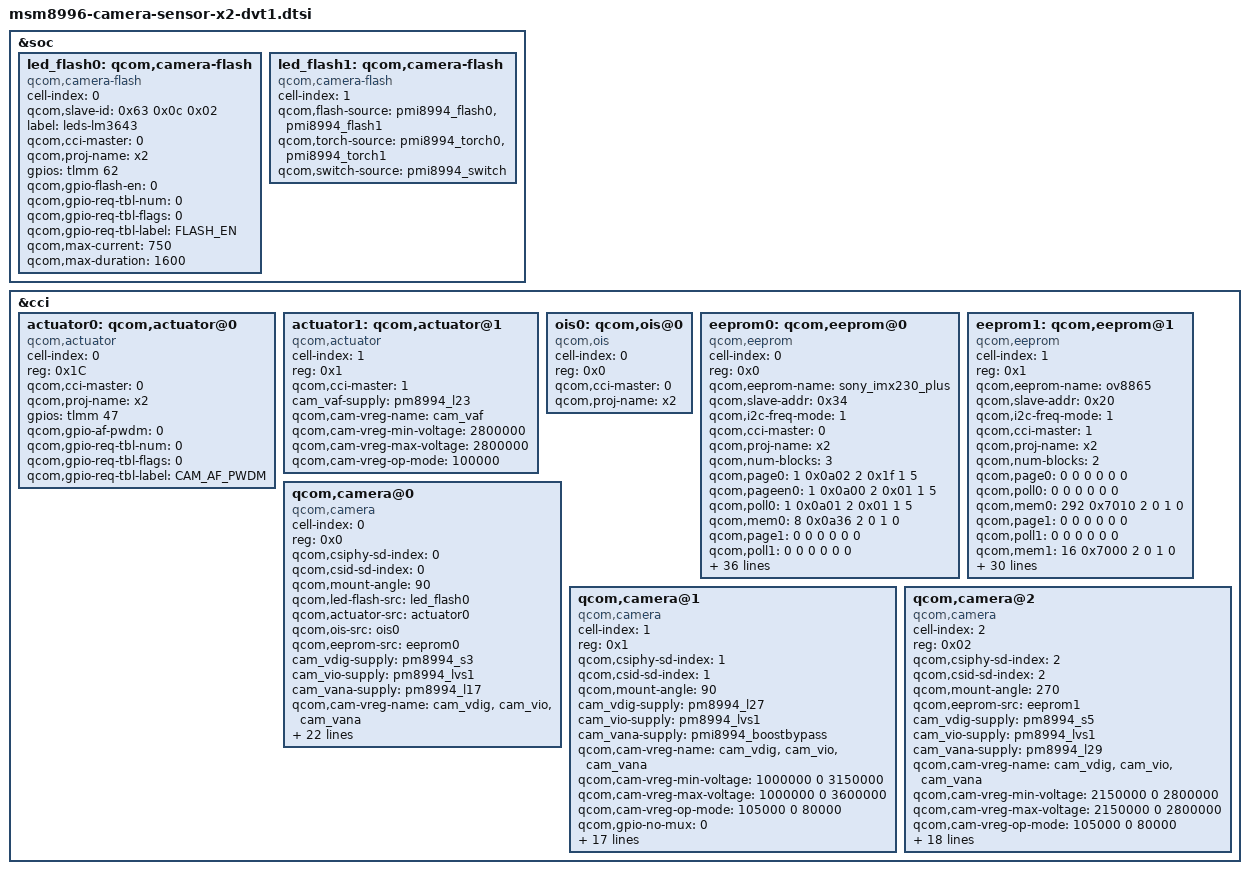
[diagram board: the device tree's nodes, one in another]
/*
 * Copyright (c) 2015 The Linux Foundation. All rights reserved.
 *
 * This program is free software; you can redistribute it and/or modify
 * it under the terms of the GNU General Public License version 2 and
 * only version 2 as published by the Free Software Foundation.
 *
 * This program is distributed in the hope that it will be useful,
 * but WITHOUT ANY WARRANTY; without even the implied warranty of
 * MERCHANTABILITY or FITNESS FOR A PARTICULAR PURPOSE.  See the
 * GNU General Public License for more details.
 */

&soc {
	led_flash0: qcom,camera-flash {
		cell-index = <0>;
		qcom,slave-id = <0x63 0x0c 0x02>;
		compatible = "qcom,camera-flash";
		label = "leds-lm3643";
		qcom,cci-master = <0>;
		qcom,proj-name = "x2";
		gpios = <&tlmm 62 0>;
		qcom,gpio-flash-en = <0>;
		qcom,gpio-req-tbl-num = <0>;
		qcom,gpio-req-tbl-flags = <0>;
		qcom,gpio-req-tbl-label = "FLASH_EN";
		qcom,max-current = <750>;
		qcom,max-duration = <1600>;
	};

	led_flash1: qcom,camera-flash {
		cell-index = <1>;
		compatible = "qcom,camera-flash";
		qcom,flash-source = <&pmi8994_flash0 &pmi8994_flash1>;
		qcom,torch-source = <&pmi8994_torch0 &pmi8994_torch1>;
		qcom,switch-source = <&pmi8994_switch>;
	};
};

&cci {
	actuator0: qcom,actuator@0 {
		cell-index = <0>;
		reg = <0x1C>;
		compatible = "qcom,actuator";
		qcom,cci-master = <0>;
		qcom,proj-name = "x2";
		gpios = <&tlmm 47 0>;
		qcom,gpio-af-pwdm = <0>;
		qcom,gpio-req-tbl-num = <0>;
		qcom,gpio-req-tbl-flags = <0>;
		qcom,gpio-req-tbl-label =  "CAM_AF_PWDM";
	};

	actuator1: qcom,actuator@1 {
		cell-index = <1>;
		reg = <0x1>;
		compatible = "qcom,actuator";
		qcom,cci-master = <1>;
		cam_vaf-supply = <&pm8994_l23>;
		qcom,cam-vreg-name = "cam_vaf";
		qcom,cam-vreg-min-voltage = <2800000>;
		qcom,cam-vreg-max-voltage = <2800000>;
		qcom,cam-vreg-op-mode = <100000>;
	};

	ois0: qcom,ois@0 {
		cell-index = <0>;
		reg = <0x0>;
		compatible = "qcom,ois";
		qcom,cci-master = <0>;
		qcom,proj-name = "x2";
		/*
		cam_vaf-supply = <&pm8994_l23>;
		qcom,cam-vreg-name = "cam_vaf";
		qcom,cam-vreg-min-voltage = <2800000>;
		qcom,cam-vreg-max-voltage = <2800000>;
		qcom,cam-vreg-op-mode = <100000>;
		*/
	};

	eeprom0: qcom,eeprom@0 {
		cell-index = <0>;
		reg = <0x0>;
		qcom,eeprom-name = "sony_imx230_plus";
		compatible = "qcom,eeprom";
		qcom,slave-addr = <0x34>;
		qcom,i2c-freq-mode = <1>;
		qcom,cci-master = <0>;
		qcom,proj-name = "x2";
		qcom,num-blocks = <3>;

		qcom,page0 = <1 0x0a02 2 0x1f 1 5>;
		qcom,pageen0 = <1 0x0a00 2 0x01 1 5>;
		qcom,poll0 = <1 0x0a01 2 0x01 1 5>;
		qcom,mem0 = <8 0x0a36 2 0 1 0>;

		qcom,page1 = <0 0 0 0 0 0>;
		qcom,poll1 = <0 0 0 0 0 0>;
		qcom,saddr1 = <0xa1>;
		qcom,mem1 = <547 0x0000 2 0 1 0>;

		qcom,page2 = <0 0 0 0 0 0>;
		qcom,poll2 = <0 0 0 0 0 0>;
		qcom,saddr2 = <0xa1>;
		qcom,mem2 = <13 0x0300 2 0 1 0>;

		cam_vdig-supply = <&pm8994_s3>;
		cam_vio-supply = <&pm8994_lvs1>;
		cam_vana-supply = <&pm8994_l17>;
		qcom,cam-vreg-name = "cam_vdig", "cam_vio", "cam_vana";
		qcom,cam-vreg-min-voltage = <1300000 0 2500000>;
		qcom,cam-vreg-max-voltage = <1300000 0 2500000>;
		qcom,cam-vreg-op-mode = <105000 0 80000>;
		qcom,gpio-no-mux = <0>;
		pinctrl-names = "cam_default", "cam_suspend";
		pinctrl-0 = <&cam_sensor_mclk0_active &cam_sensor_rear_active>;
		pinctrl-1 = <&cam_sensor_mclk0_suspend &cam_sensor_rear_suspend>;
		gpios = <&tlmm 13 0>,
			<&tlmm 47 0>,
			<&tlmm 29 0>;
		qcom,gpio-reset = <1>;
		qcom,gpio-standby = <2>;
		qcom,gpio-req-tbl-num = <0 1 2>;
		qcom,gpio-req-tbl-flags = <1 0 0>;
		qcom,gpio-req-tbl-label = "CAMIF_MCLK0",
					  "CAM_AF0",
					  "CAM_STANDBY0";
		qcom,cam-power-seq-type = "sensor_vreg", "sensor_vreg", "sensor_vreg",
			"sensor_gpio", "sensor_gpio" , "sensor_clk";
		qcom,cam-power-seq-val = "cam_vdig", "cam_vana", "cam_vio",
			"sensor_gpio_reset", "sensor_gpio_standby","sensor_cam_mclk";
		qcom,cam-power-seq-cfg-val = <1 1 1 1 1 24000000>;
		qcom,cam-power-seq-delay = <1 1 1 30 30 5>;
		status = "ok";
		clocks = <&clock_mmss clk_mclk0_clk_src>,
				<&clock_mmss clk_camss_mclk0_clk>;
		clock-names = "cam_src_clk", "cam_clk";
	};

	eeprom1: qcom,eeprom@1 {
		cell-index = <1>;
		reg = <0x1>;
		qcom,eeprom-name = "ov8865";
		compatible = "qcom,eeprom";
		qcom,slave-addr = <0x20>;
		qcom,i2c-freq-mode = <1>;
		qcom,cci-master = <1>;
		qcom,proj-name = "x2";
		qcom,num-blocks = <2>;

		qcom,page0 = <0 0 0 0 0 0>;
		qcom,poll0 = <0 0 0 0 0 0>;
		qcom,mem0 = <292 0x7010 2 0 1 0>;

		qcom,page1 = <0 0 0 0 0 0>;
		qcom,poll1 = <0 0 0 0 0 0>;
		qcom,mem1 = <16 0x7000 2 0 1 0>;

		cam_vdig-supply = <&pm8994_s5>;
		cam_vio-supply = <&pm8994_lvs1>;
		cam_vana-supply = <&pm8994_l29>;
		qcom,cam-vreg-name = "cam_vdig", "cam_vio", "cam_vana";
		qcom,cam-vreg-min-voltage = <2150000 0 2800000>;
		qcom,cam-vreg-max-voltage = <2150000 0 2800000>;
		qcom,cam-vreg-op-mode = <105000 0 80000>;
		qcom,gpio-no-mux = <0>;
		pinctrl-names = "cam_default", "cam_suspend";
		pinctrl-0 = <&cam_sensor_mclk2_active &cam_sensor_front_active>;
		pinctrl-1 = <&cam_sensor_mclk2_suspend &cam_sensor_front_suspend>;
		gpios = <&tlmm 15 0>,
			<&tlmm 23 0>,
			<&tlmm 26 0>;
		qcom,gpio-reset = <1>;
		qcom,gpio-standby = <2>;
		qcom,gpio-req-tbl-num = <0 1 2>;
		qcom,gpio-req-tbl-flags = <1 0 0>;
		qcom,gpio-req-tbl-label = "CAMIF_MCLK2",
					  "CAM_RESET2",
					  "CAM_STANDBY2";
		qcom,cam-power-seq-type = "sensor_vreg", "sensor_vreg", "sensor_vreg",
			"sensor_gpio", "sensor_gpio" , "sensor_clk";
		qcom,cam-power-seq-val = "cam_vdig", "cam_vana", "cam_vio",
			"sensor_gpio_reset", "sensor_gpio_standby","sensor_cam_mclk";
		qcom,cam-power-seq-cfg-val = <1 1 1 1 1 24000000>;
		qcom,cam-power-seq-delay = <1 1 1 30 30 5>;
		status = "ok";
		clocks = <&clock_mmss clk_mclk2_clk_src>,
				<&clock_mmss clk_camss_mclk2_clk>;
		clock-names = "cam_src_clk", "cam_clk";
	};

	qcom,camera@0 {
		cell-index = <0>;
		compatible = "qcom,camera";
		reg = <0x0>;
		qcom,csiphy-sd-index = <0>;
		qcom,csid-sd-index = <0>;
		qcom,mount-angle = <90>;
		qcom,led-flash-src = <&led_flash0>;
		qcom,actuator-src = <&actuator0>;
		qcom,ois-src = <&ois0>;
		qcom,eeprom-src = <&eeprom0>;
		cam_vdig-supply = <&pm8994_s3>;
		cam_vio-supply = <&pm8994_lvs1>;
		cam_vana-supply = <&pm8994_l17>;
		qcom,cam-vreg-name = "cam_vdig", "cam_vio", "cam_vana";
		qcom,cam-vreg-min-voltage = <1300000 0 2500000>;
		qcom,cam-vreg-max-voltage = <1300000 0 2500000>;
		qcom,cam-vreg-op-mode = <105000 0 80000>;
		qcom,gpio-no-mux = <0>;
		pinctrl-names = "cam_default", "cam_suspend";
		pinctrl-0 = <&cam_sensor_mclk0_active &cam_sensor_rear_active>;
		pinctrl-1 = <&cam_sensor_mclk0_suspend &cam_sensor_rear_suspend>;
		gpios = <&tlmm 13 0>,
			<&tlmm 62 0>,
			<&tlmm 47 0>,
			<&tlmm 29 0>;
		qcom,gpio-flash-en = <1>;
		qcom,gpio-vaf = <2>;
		qcom,gpio-standby = <3>;
		qcom,gpio-req-tbl-num = <0 1 2 3>;
		qcom,gpio-req-tbl-flags = <1 0 0 0>;
		qcom,gpio-req-tbl-label = "CAMIF_MCLK0",
					  "CAM_FLASH0",
					  "CAM_AF0",
					  "CAM_STANDBY0";
		qcom,sensor-position = <0>;
		qcom,sensor-mode = <0>;
		qcom,cci-master = <0>;
		qcom,proj-name = "x2";
		status = "ok";
		clocks = <&clock_mmss clk_mclk0_clk_src>,
				<&clock_mmss clk_camss_mclk0_clk>;
		clock-names = "cam_src_clk", "cam_clk";
	};

	qcom,camera@1 {
		cell-index = <1>;
		compatible = "qcom,camera";
		reg = <0x1>;
		qcom,csiphy-sd-index = <1>;
		qcom,csid-sd-index = <1>;
		qcom,mount-angle = <90>;
		cam_vdig-supply = <&pm8994_l27>;
		cam_vio-supply = <&pm8994_lvs1>;
		cam_vana-supply = <&pmi8994_boostbypass>;
		qcom,cam-vreg-name = "cam_vdig", "cam_vio", "cam_vana";
		qcom,cam-vreg-min-voltage = <1000000 0 3150000>;
		qcom,cam-vreg-max-voltage = <1000000 0 3600000>;
		qcom,cam-vreg-op-mode = <105000 0 80000>;
		qcom,gpio-no-mux = <0>;
		pinctrl-names = "cam_default", "cam_suspend";
		pinctrl-0 = <&cam_sensor_mclk1_active &cam_sensor_rear2_active>;
		pinctrl-1 = <&cam_sensor_mclk1_suspend &cam_sensor_rear2_suspend>;
		gpios = <&tlmm 14 0>,
			<&tlmm 63 0>,
			<&tlmm 62 0>;
		qcom,gpio-reset = <1>;
		qcom,gpio-standby = <2>;
		qcom,gpio-req-tbl-num = <0 1 2>;
		qcom,gpio-req-tbl-flags = <1 0 0>;
		qcom,gpio-req-tbl-label = "CAMIF_MCLK1",
					  "CAM_RESET1",
					  "CAM_STANDBY1";
		qcom,sensor-position = <0>;
		qcom,sensor-mode = <0>;
		qcom,cci-master = <0>;
		qcom,proj-name = "x2";
		status = "ok";
		clocks = <&clock_mmss clk_mclk1_clk_src>,
			<&clock_mmss clk_camss_mclk1_clk>;
		clock-names = "cam_src_clk", "cam_clk";
	};

	qcom,camera@2 {
		cell-index = <2>;
		compatible = "qcom,camera";
		reg = <0x02>;
		qcom,csiphy-sd-index = <2>;
		qcom,csid-sd-index = <2>;
		qcom,mount-angle = <270>;
		qcom,eeprom-src = <&eeprom1>;
		cam_vdig-supply = <&pm8994_s5>;
		cam_vio-supply = <&pm8994_lvs1>;
		cam_vana-supply = <&pm8994_l29>;
		qcom,cam-vreg-name = "cam_vdig", "cam_vio", "cam_vana";
		qcom,cam-vreg-min-voltage = <2150000 0 2800000>;
		qcom,cam-vreg-max-voltage = <2150000 0 2800000>;
		qcom,cam-vreg-op-mode = <105000 0 80000>;
		qcom,gpio-no-mux = <0>;
		pinctrl-names = "cam_default", "cam_suspend";
		pinctrl-0 = <&cam_sensor_mclk2_active &cam_sensor_front_active>;
		pinctrl-1 = <&cam_sensor_mclk2_suspend &cam_sensor_front_suspend>;
		gpios = <&tlmm 15 0>,
			<&tlmm 23 0>,
			<&tlmm 26 0>;
		qcom,gpio-reset = <1>;
		qcom,gpio-standby = <2>;
		qcom,gpio-req-tbl-num = <0 1 2>;
		qcom,gpio-req-tbl-flags = <1 0 0>;
		qcom,gpio-req-tbl-label = "CAMIF_MCLK2",
					  "CAM_RESET2",
					  "CAM_STANDBY2";
		qcom,sensor-position = <1>;
		qcom,sensor-mode = <0>;
		qcom,cci-master = <1>;
		qcom,proj-name = "x2";
		status = "ok";
		clocks = <&clock_mmss clk_mclk2_clk_src>,
			<&clock_mmss clk_camss_mclk2_clk>;
		clock-names = "cam_src_clk", "cam_clk";
	};
};
